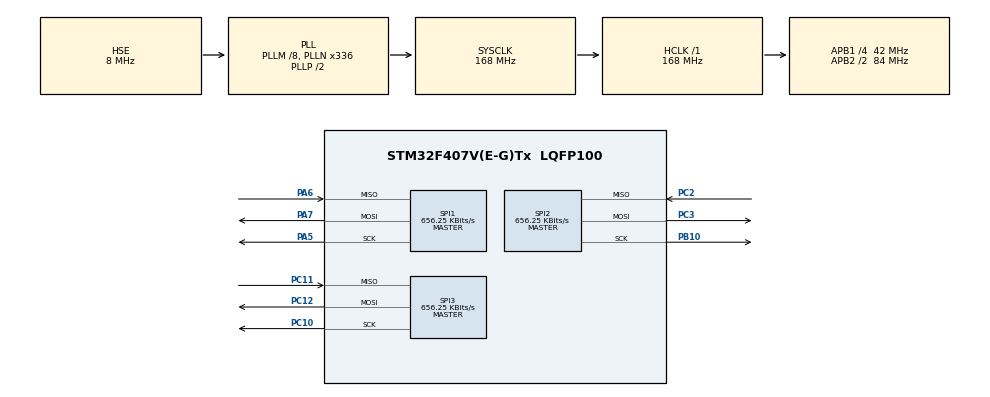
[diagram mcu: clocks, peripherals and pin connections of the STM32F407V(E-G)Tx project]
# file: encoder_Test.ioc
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Mcu.Family=STM32F4
Mcu.Name=STM32F407V(E-G)Tx
Mcu.Package=LQFP100
NVIC.PriorityGroup=NVIC_PRIORITYGROUP_0
PA5.Mode=Full_Duplex_Master
PA5.Signal=SPI1_SCK
PA6.Mode=Full_Duplex_Master
PA6.Signal=SPI1_MISO
PA7.Mode=Full_Duplex_Master
PA7.Signal=SPI1_MOSI
PB10.Mode=Full_Duplex_Master
PB10.Signal=SPI2_SCK
PC10.Mode=Full_Duplex_Master
PC10.Signal=SPI3_SCK
PC11.Mode=Full_Duplex_Master
PC11.Signal=SPI3_MISO
PC12.Mode=Full_Duplex_Master
PC12.Signal=SPI3_MOSI
PC2.Mode=Full_Duplex_Master
PC2.Signal=SPI2_MISO
PC3.Mode=Full_Duplex_Master
PC3.Signal=SPI2_MOSI
PH0-OSC_IN.Mode=HSE-External-Oscillator
PH0-OSC_IN.Signal=RCC_OSC_IN
PH1-OSC_OUT.Mode=HSE-External-Oscillator
PH1-OSC_OUT.Signal=RCC_OSC_OUT
ProjectManager.HeapSize=0x200
ProjectManager.StackSize=0x400
ProjectManager.TargetToolchain=STM32CubeIDE
RCC.48MHZClocksFreq_Value=48000000
RCC.AHBFreq_Value=168000000
RCC.APB1CLKDivider=RCC_HCLK_DIV4
RCC.APB1Freq_Value=42000000
RCC.APB1TimFreq_Value=84000000
RCC.APB2CLKDivider=RCC_HCLK_DIV2
RCC.APB2Freq_Value=84000000
RCC.APB2TimFreq_Value=168000000
RCC.CortexFreq_Value=168000000
RCC.HCLKFreq_Value=168000000
RCC.HSE_VALUE=8000000
RCC.HSI_VALUE=16000000
RCC.PLLM=8
RCC.PLLN=336
RCC.PLLQ=7
RCC.PLLSourceVirtual=RCC_PLLSOURCE_HSE
RCC.SYSCLKFreq_VALUE=168000000
RCC.SYSCLKSource=RCC_SYSCLKSOURCE_PLLCLK
RCC.VCOOutputFreq_Value=336000000
SPI1.BaudRatePrescaler=SPI_BAUDRATEPRESCALER_128
SPI1.CLKPhase=SPI_PHASE_2EDGE
SPI1.CLKPolarity=SPI_POLARITY_HIGH
SPI1.CalculateBaudRate=656.25 KBits/s
SPI1.DataSize=SPI_DATASIZE_16BIT
SPI1.Direction=SPI_DIRECTION_2LINES
SPI1.Mode=SPI_MODE_MASTER
SPI1.VirtualType=VM_MASTER
SPI2.BaudRatePrescaler=SPI_BAUDRATEPRESCALER_64
SPI2.CLKPhase=SPI_PHASE_2EDGE
SPI2.CLKPolarity=SPI_POLARITY_HIGH
SPI2.CalculateBaudRate=656.25 KBits/s
SPI2.DataSize=SPI_DATASIZE_16BIT
SPI2.Direction=SPI_DIRECTION_2LINES
SPI2.Mode=SPI_MODE_MASTER
SPI2.VirtualType=VM_MASTER
SPI3.BaudRatePrescaler=SPI_BAUDRATEPRESCALER_64
SPI3.CLKPhase=SPI_PHASE_2EDGE
SPI3.CLKPolarity=SPI_POLARITY_HIGH
SPI3.CalculateBaudRate=656.25 KBits/s
SPI3.DataSize=SPI_DATASIZE_16BIT
SPI3.Direction=SPI_DIRECTION_2LINES
SPI3.Mode=SPI_MODE_MASTER
SPI3.VirtualType=VM_MASTER
board=STM32F407G-DISC1

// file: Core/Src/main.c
/* USER CODE BEGIN Header */
/**
  ******************************************************************************
  * @file           : main.c
  * @brief          : Main program body
  ******************************************************************************
  * @attention
  *
  * Copyright (c) 2026 STMicroelectronics.
  * All rights reserved.
  *
  * This software is licensed under terms that can be found in the LICENSE file
  * in the root directory of this software component.
  * If no LICENSE file comes with this software, it is provided AS-IS.
  *
  ******************************************************************************
  */
/* USER CODE END Header */
#include "main.h"

/* USER CODE BEGIN Includes */
#include "fenac_encoder.h"
/* USER CODE END Includes */

SPI_HandleTypeDef hspi1;
SPI_HandleTypeDef hspi2;
SPI_HandleTypeDef hspi3;

/* USER CODE BEGIN PV */
FenacEncoder_t encoder1;
FenacEncoder_t encoder2;
FenacEncoder_t encoder3;
/* USER CODE END PV */

void SystemClock_Config(void);
static void MX_GPIO_Init(void);
static void MX_SPI1_Init(void);
static void MX_SPI2_Init(void);
static void MX_SPI3_Init(void);

int main(void)
{

  /* MCU Configuration--------------------------------------------------------*/

  /* Reset of all peripherals, Initializes the Flash interface and the Systick. */
  HAL_Init();

  /* Configure the system clock */
  SystemClock_Config();

  /* Initialize all configured peripherals */
  MX_GPIO_Init();
  MX_SPI1_Init();
  MX_SPI2_Init();
  MX_SPI3_Init();
  /* USER CODE BEGIN 2 */
  //Fenac_Init(&encoder1, &hspi1); // 1. Enkoder
  Fenac_Init(&encoder2, &hspi2); // 2. Enkoder
  // Fenac_Init(&encoder3, &hspi3); // 3. Enkoder
  /* USER CODE END 2 */

  /* Infinite loop */
  while (1)
  {

    /* USER CODE BEGIN 3 */
	  //Fenac_Read_SSI(&encoder1);
	  Fenac_Read_SSI(&encoder2);
	  // Fenac_Read_SSI(&encoder3);
  }
  /* USER CODE END 3 */
}

void SystemClock_Config(void)
{
  RCC_OscInitTypeDef RCC_OscInitStruct = {0};
  RCC_ClkInitTypeDef RCC_ClkInitStruct = {0};

  /** Configure the main internal regulator output voltage
  */
  __HAL_RCC_PWR_CLK_ENABLE();
  __HAL_PWR_VOLTAGESCALING_CONFIG(PWR_REGULATOR_VOLTAGE_SCALE1);

  /** Initializes the RCC Oscillators according to the specified parameters
  * in the RCC_OscInitTypeDef structure.
  */
  RCC_OscInitStruct.OscillatorType = RCC_OSCILLATORTYPE_HSE;
  RCC_OscInitStruct.HSEState = RCC_HSE_ON;
  RCC_OscInitStruct.PLL.PLLState = RCC_PLL_ON;
  RCC_OscInitStruct.PLL.PLLSource = RCC_PLLSOURCE_HSE;
  RCC_OscInitStruct.PLL.PLLM = 8;
  RCC_OscInitStruct.PLL.PLLN = 336;
  RCC_OscInitStruct.PLL.PLLP = RCC_PLLP_DIV2;
  RCC_OscInitStruct.PLL.PLLQ = 7;
  if (HAL_RCC_OscConfig(&RCC_OscInitStruct) != HAL_OK)
  {
    Error_Handler();
  }

  /** Initializes the CPU, AHB and APB buses clocks
  */
  RCC_ClkInitStruct.ClockType = RCC_CLOCKTYPE_HCLK|RCC_CLOCKTYPE_SYSCLK
                              |RCC_CLOCKTYPE_PCLK1|RCC_CLOCKTYPE_PCLK2;
  RCC_ClkInitStruct.SYSCLKSource = RCC_SYSCLKSOURCE_PLLCLK;
  RCC_ClkInitStruct.AHBCLKDivider = RCC_SYSCLK_DIV1;
  RCC_ClkInitStruct.APB1CLKDivider = RCC_HCLK_DIV4;
  RCC_ClkInitStruct.APB2CLKDivider = RCC_HCLK_DIV2;

  if (HAL_RCC_ClockConfig(&RCC_ClkInitStruct, FLASH_LATENCY_5) != HAL_OK)
  {
    Error_Handler();
  }
}

static void MX_SPI1_Init(void)
{

  /* SPI1 parameter configuration*/
  hspi1.Instance = SPI1;
  hspi1.Init.Mode = SPI_MODE_MASTER;
  hspi1.Init.Direction = SPI_DIRECTION_2LINES;
  hspi1.Init.DataSize = SPI_DATASIZE_16BIT;
  hspi1.Init.CLKPolarity = SPI_POLARITY_HIGH;
  hspi1.Init.CLKPhase = SPI_PHASE_2EDGE;
  hspi1.Init.NSS = SPI_NSS_SOFT;
  hspi1.Init.BaudRatePrescaler = SPI_BAUDRATEPRESCALER_128;
  hspi1.Init.FirstBit = SPI_FIRSTBIT_MSB;
  hspi1.Init.TIMode = SPI_TIMODE_DISABLE;
  hspi1.Init.CRCCalculation = SPI_CRCCALCULATION_DISABLE;
  hspi1.Init.CRCPolynomial = 10;
  if (HAL_SPI_Init(&hspi1) != HAL_OK)
  {
    Error_Handler();
  }

}

static void MX_SPI2_Init(void)
{

  /* SPI2 parameter configuration*/
  hspi2.Instance = SPI2;
  hspi2.Init.Mode = SPI_MODE_MASTER;
  hspi2.Init.Direction = SPI_DIRECTION_2LINES;
  hspi2.Init.DataSize = SPI_DATASIZE_16BIT;
  hspi2.Init.CLKPolarity = SPI_POLARITY_HIGH;
  hspi2.Init.CLKPhase = SPI_PHASE_2EDGE;
  hspi2.Init.NSS = SPI_NSS_SOFT;
  hspi2.Init.BaudRatePrescaler = SPI_BAUDRATEPRESCALER_64;
  hspi2.Init.FirstBit = SPI_FIRSTBIT_MSB;
  hspi2.Init.TIMode = SPI_TIMODE_DISABLE;
  hspi2.Init.CRCCalculation = SPI_CRCCALCULATION_DISABLE;
  hspi2.Init.CRCPolynomial = 10;
  if (HAL_SPI_Init(&hspi2) != HAL_OK)
  {
    Error_Handler();
  }

}

static void MX_SPI3_Init(void)
{

  /* SPI3 parameter configuration*/
  hspi3.Instance = SPI3;
  hspi3.Init.Mode = SPI_MODE_MASTER;
  hspi3.Init.Direction = SPI_DIRECTION_2LINES;
  hspi3.Init.DataSize = SPI_DATASIZE_16BIT;
  hspi3.Init.CLKPolarity = SPI_POLARITY_HIGH;
  hspi3.Init.CLKPhase = SPI_PHASE_2EDGE;
  hspi3.Init.NSS = SPI_NSS_SOFT;
  hspi3.Init.BaudRatePrescaler = SPI_BAUDRATEPRESCALER_64;
  hspi3.Init.FirstBit = SPI_FIRSTBIT_MSB;
  hspi3.Init.TIMode = SPI_TIMODE_DISABLE;
  hspi3.Init.CRCCalculation = SPI_CRCCALCULATION_DISABLE;
  hspi3.Init.CRCPolynomial = 10;
  if (HAL_SPI_Init(&hspi3) != HAL_OK)
  {
    Error_Handler();
  }

}

static void MX_GPIO_Init(void)
{

  /* GPIO Ports Clock Enable */
  __HAL_RCC_GPIOH_CLK_ENABLE();
  __HAL_RCC_GPIOC_CLK_ENABLE();
  __HAL_RCC_GPIOA_CLK_ENABLE();
  __HAL_RCC_GPIOB_CLK_ENABLE();

}

void Error_Handler(void)
{
  __disable_irq();
  while (1)
  {
  }
}
